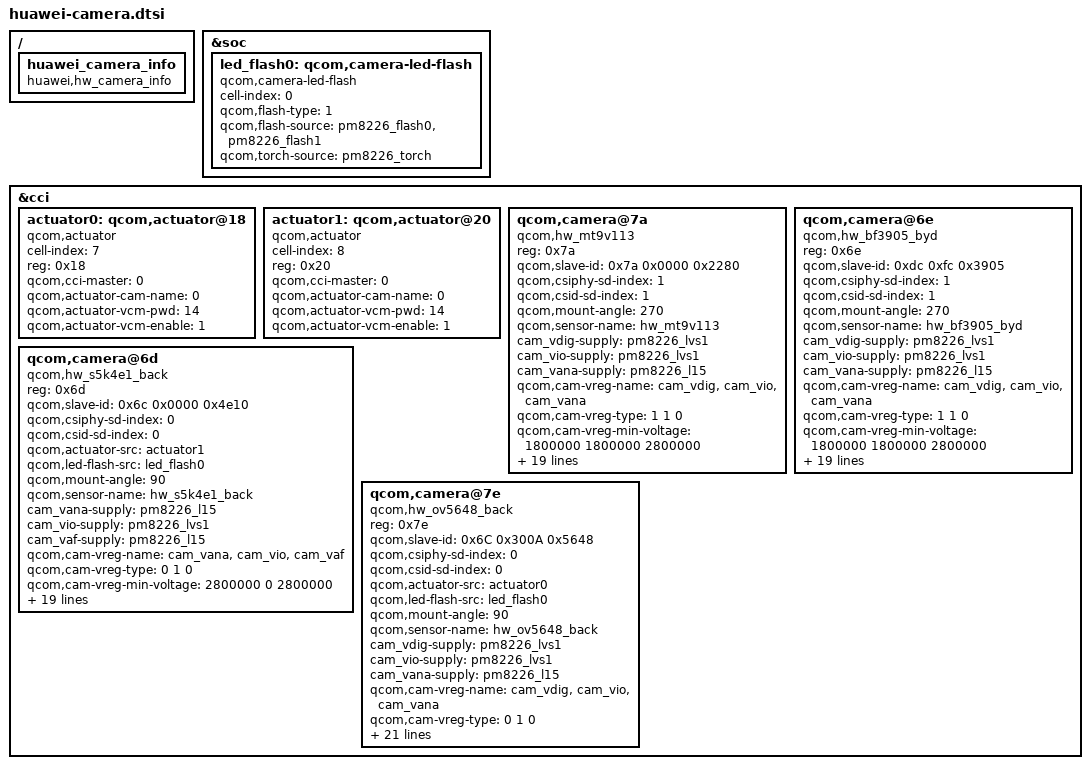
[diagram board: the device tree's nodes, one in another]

 / {
        huawei_camera_info {
                  compatible = "huawei,hw_camera_info";
                  status = "ok";
        };
};

&soc {

	led_flash0: qcom,camera-led-flash {
		cell-index = <0>;
		compatible = "qcom,camera-led-flash";
		qcom,flash-type = <1>;
		qcom,flash-source = <&pm8226_flash0 &pm8226_flash1>;
		qcom,torch-source = <&pm8226_torch>;
	};
};

&cci {
	actuator0: qcom,actuator@18 {
		cell-index = <7>;
		reg = <0x18>;
		compatible = "qcom,actuator";
		qcom,cci-master = <0>;
		qcom,actuator-cam-name = <0>;
		qcom,actuator-vcm-pwd = <14>;
		qcom,actuator-vcm-enable = <1>;
	};
	actuator1: qcom,actuator@20 {
		cell-index = <8>;
		reg = <0x20>;
		compatible = "qcom,actuator";
		qcom,cci-master = <0>;
		qcom,actuator-cam-name = <0>;
		qcom,actuator-vcm-pwd = <14>;
		qcom,actuator-vcm-enable = <1>;
	};
	
	qcom,camera@7a {
		compatible = "qcom,hw_mt9v113";
		reg = <0x7a>;
		qcom,slave-id = <0x7a 0x0000 0x2280>;
		qcom,csiphy-sd-index = <1>;
		qcom,csid-sd-index = <1>;
		qcom,mount-angle = <270>;
		qcom,sensor-name = "hw_mt9v113";
		cam_vdig-supply = <&pm8226_lvs1>;
		cam_vio-supply = <&pm8226_lvs1>;
		cam_vana-supply = <&pm8226_l15>;
		qcom,cam-vreg-name = "cam_vdig", "cam_vio", "cam_vana";
		qcom,cam-vreg-type = <1 1 0>;
		qcom,cam-vreg-min-voltage = <1800000 1800000 2800000>;
		qcom,cam-vreg-max-voltage = <1800000 1800000 2800000>;
		qcom,cam-vreg-op-mode = <0 0 45000>;
		qcom,gpio-no-mux = <0>;
		gpios = <&msmgpio 26 0>,
			<&msmgpio 28 0>,
			<&msmgpio 35 0>;
		qcom,gpio-reset = <1>;
		qcom,gpio-standby = <2>;
		qcom,gpio-req-tbl-num = <0 1 2>;
		qcom,gpio-req-tbl-flags = <1 0 0>;
		qcom,gpio-req-tbl-label = "CAMIF_MCLK",
				"CAM_RESET",
				"CAM_STANDBY";
		qcom,gpio-set-tbl-num = <1 2>;
		qcom,gpio-set-tbl-flags = <0 0>;
		qcom,gpio-set-tbl-delay = <1000 4000>;
		qcom,csi-lane-assign = <0x4320>;
		qcom,csi-lane-mask = <0x3>;
		qcom,sensor-position = <1>;
		qcom,sensor-mode = <1>;
		qcom,cci-master = <0>;
		status = "ok";
	};
	qcom,camera@6e {
		compatible = "qcom,hw_bf3905_byd";
		reg = <0x6e>;
		qcom,slave-id = <0xdc 0xfc 0x3905>;
		qcom,csiphy-sd-index = <1>;
		qcom,csid-sd-index = <1>;
		qcom,mount-angle = <270>;
		qcom,sensor-name = "hw_bf3905_byd";
		cam_vdig-supply = <&pm8226_lvs1>;
		cam_vio-supply = <&pm8226_lvs1>;
		cam_vana-supply = <&pm8226_l15>;
		qcom,cam-vreg-name = "cam_vdig", "cam_vio", "cam_vana";
		qcom,cam-vreg-type = <1 1 0>;
		qcom,cam-vreg-min-voltage = <1800000 1800000 2800000>;
		qcom,cam-vreg-max-voltage = <1800000 1800000 2800000>;
		qcom,cam-vreg-op-mode = <0 0 45000>;
		qcom,gpio-no-mux = <0>;
		gpios = <&msmgpio 26 0>,
			<&msmgpio 28 0>,
			<&msmgpio 35 0>;
		qcom,gpio-reset = <1>;
		qcom,gpio-standby = <2>;
		qcom,gpio-req-tbl-num = <0 1 2>;
		qcom,gpio-req-tbl-flags = <1 0 0>;
		qcom,gpio-req-tbl-label = "CAMIF_MCLK",
				"CAM_RESET",
				"CAM_STANDBY";
		qcom,gpio-set-tbl-num = <1 2>;
		qcom,gpio-set-tbl-flags = <0 0>;
		qcom,gpio-set-tbl-delay = <1000 4000>;
		qcom,csi-lane-assign = <0x4E>;
		qcom,csi-lane-mask = <0x3>;
		qcom,sensor-position = <1>;
		qcom,sensor-mode = <1>;
		qcom,cci-master = <0>;
		status = "ok";
	};
	qcom,camera@6d{
		compatible = "qcom,hw_s5k4e1_back";
		reg = <0x6d>;
		qcom,slave-id = <0x6c 0x0000 0x4e10>;
		qcom,csiphy-sd-index = <0>;
		qcom,csid-sd-index = <0>;
		qcom,actuator-src = <&actuator1>;
		qcom,led-flash-src = <&led_flash0>;
		qcom,mount-angle = <90>;
		qcom,sensor-name = "hw_s5k4e1_back";
		cam_vana-supply = <&pm8226_l15>;
		cam_vio-supply = <&pm8226_lvs1>;
		cam_vaf-supply = <&pm8226_l15>;
		qcom,cam-vreg-name ="cam_vana", "cam_vio", "cam_vaf";
		qcom,cam-vreg-type = <0 1 0>;
		qcom,cam-vreg-min-voltage = <2800000 0 2800000>;
		qcom,cam-vreg-max-voltage = <2800000 0 2800000>;
		qcom,cam-vreg-op-mode = <80000 0 100000>;
		qcom,gpio-no-mux = <0>;
		gpios = <&msmgpio 26 0>,
			<&msmgpio 36 0>,
			<&msmgpio 37 0>;
		qcom,gpio-reset = <2>;
		qcom,gpio-standby = <1>;
		qcom,gpio-req-tbl-num = <0 1 2>;
		qcom,gpio-req-tbl-flags = <1 0 0>;
		qcom,gpio-req-tbl-label = "CAMIF_MCLK",
			"CAM_STANDBY",
			"CAM_RESET";
		qcom,gpio-set-tbl-num = <2>;
		qcom,gpio-set-tbl-flags = <2>;
		qcom,gpio-set-tbl-delay = <2500>;
		qcom,csi-lane-assign = <0x4320>;
		qcom,csi-lane-mask = <0x1f>;
		qcom,sensor-position = <0>;
		qcom,sensor-mode = <0>;
		qcom,sensor-type = <0>;
		qcom,cci-master = <0>;
		status = "ok";
	};
	qcom,camera@7e {
		compatible = "qcom,hw_ov5648_back";
		reg = <0x7e>;
		qcom,slave-id = <0x6C 0x300A 0x5648>;
		qcom,csiphy-sd-index = <0>;
		qcom,csid-sd-index = <0>;
		qcom,actuator-src = <&actuator0>;
		qcom,led-flash-src = <&led_flash0>;
		qcom,mount-angle = <90>;
		qcom,sensor-name = "hw_ov5648_back";
		cam_vdig-supply = <&pm8226_lvs1>;
		cam_vio-supply = <&pm8226_lvs1>;
		cam_vana-supply = <&pm8226_l15>;
		qcom,cam-vreg-name = "cam_vdig", "cam_vio", "cam_vana";
		qcom,cam-vreg-type = <0 1 0>;
		qcom,cam-vreg-min-voltage = <1800000 1800000 2800000>;
		qcom,cam-vreg-max-voltage = <1800000 1800000 2800000>;
		qcom,cam-vreg-op-mode = <20000 0 80000>;
		qcom,gpio-no-mux = <0>;
		gpios = <&msmgpio 26 0>,
			<&msmgpio 37 0>,
			<&msmgpio 36 0>;
		qcom,gpio-reset = <1>;
		qcom,gpio-standby = <2>;
		qcom,gpio-req-tbl-num = <0 1 2>;
		qcom,gpio-req-tbl-flags = <1 0 0>;
		qcom,gpio-req-tbl-label = "CAMIF_MCLK",
				"CAM_RESET",
				"CAM_STANDBY";
		qcom,gpio-set-tbl-num = <0 1 2>;
		qcom,gpio-set-tbl-flags = <1 0 0>;
		qcom,gpio-set-tbl-delay = <1000 4000 1000>;
		qcom,csi-lane-assign = <0x4320>;
		qcom,csi-lane-mask = <0x1f>;
		qcom,sensor-position = <0>;
		qcom,sensor-mode = <0>;
		qcom,cci-master = <0>;
		status = "ok";
	};
};

